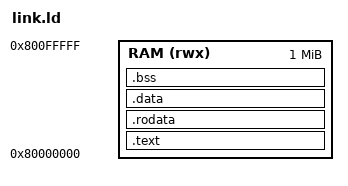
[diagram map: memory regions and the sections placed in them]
OUTPUT_ARCH(riscv)
ENTRY(_start)

MEMORY
{
    RAM (rwx) : ORIGIN = 0x80000000, LENGTH = 1M
}

SECTIONS
{
    .text : {
        *(.init)
        *(.text*)
    } > RAM

    .rodata : {
        *(.rodata*)
        *(.srodata*)
    } > RAM

    .data : {
        *(.data*)
        *(.sdata*)
    } > RAM

    .bss (NOLOAD) : {
        _bss_start = .;
        *(.bss*)
        *(.sbss*)
        *(COMMON)
        _bss_end = .;
    } > RAM

    . = ALIGN(16);
    . = . + 0x1000; /* 4 KiB stack */
    _stack_top = .;
}
